VERSION ""

NS_ :

BS_:

BU_:

BO_ 915 VCU_EPB_1: 8 Vector__XXX
 SG_ VCU_WarnLampSts : 2|2@0+ (1,0) [3|0] "" Vector__XXX
 SG_ EPB_VehiclelongitudinalAcceleration : 16|12@0+ (0.01,-20.48) [20.46|-20.48] "m/s2" Vector__XXX

BO_ 792 ABS_2: 8 Vector__XXX
 SG_ ABS_EBDFaultSts : 8|1@0+ (1,0) [1|0] "" Vector__XXX
 SG_ ABS_ESCEnableSwSts : 9|1@0+ (1,0) [1|0] "" Vector__XXX
 SG_ ABS_ABSFaultSts : 10|1@0+ (1,0) [1|0] "" Vector__XXX
 SG_ ABS_AEBActiveSts : 11|1@0+ (1,0) [1|0] "" Vector__XXX
 SG_ ABS_AEBAvailableSts : 12|1@0+ (1,0) [1|0] "" Vector__XXX
 SG_ ABS_ABSActiveSts : 13|1@0+ (1,0) [1|0] "" Vector__XXX
 SG_ ABS_ESCFaultSts : 14|1@0+ (1,0) [1|0] "" Vector__XXX
 SG_ ABS_BrakePedalActiveSts : 15|1@0+ (1,0) [1|0] "" Vector__XXX
 SG_ ABS_EPBBrakeReq : 16|1@0+ (1,0) [1|0] "" Vector__XXX
 SG_ ABS_EBDWarnLamp : 17|1@0+ (1,0) [1|0] "" Vector__XXX
 SG_ ABS_ABSWarnLamp : 18|1@0+ (1,0) [1|0] "" Vector__XXX
 SG_ ABS_CarbonBrushFaulSts : 19|1@0+ (1,0) [1|0] "" Vector__XXX
 SG_ ABS_ACCControlActiveSts : 20|1@0+ (1,0) [1|0] "" Vector__XXX
 SG_ ABS_CurrentConfiguration : 21|1@0+ (1,0) [1|0] "" Vector__XXX
 SG_ ABS_ACCControlAvailableSts : 22|1@0+ (1,0) [1|0] "" Vector__XXX
 SG_ ABS_VehSpeedError : 23|1@0+ (1,0) [1|0] "" Vector__XXX
 SG_ ABS_VehSpeed : 32|16@0+ (0.01,0) [655.34|0] "kph" Vector__XXX

BO_ 713 ACM_IDM_4: 8 Vector__XXX
 SG_ IDM__LDW_SensSts : 22|2@0+ (1,0) [3|0] "" Vector__XXX

BO_ 1040 MCU_1: 8 Vector__XXX
 SG_ MCU_MotorSpd : 24|16@0+ (0.5,-12000) [12000|-12000] "rpm" Vector__XXX
 SG_ MCU_ActTorq : 40|16@0+ (0.05,-300) [300|-300] "Nm" Vector__XXX

BO_ 1312 TBOX_1: 8 Vector__XXX
 SG_ TBOX_RemoteAntiTheftReq : 16|2@0+ (1,0) [3|0] "" Vector__XXX

BO_ 710 ACM_IDM_4: 8 Vector__XXX
 SG_ IDM__AEB_EnableSts : 0|2@0+ (1,0) [3|0] "" Vector__XXX
 SG_ IDM__FCW_EnableSts : 2|2@0+ (1,0) [3|0] "" Vector__XXX
 SG_ IDM__LDW_EnableSts : 4|2@0+ (1,0) [3|0] "" Vector__XXX
 SG_ IDM__LCK_EnableSts : 6|2@0+ (1,0) [3|0] "" Vector__XXX
 SG_ IDM__TJA_EnableSts : 8|2@0+ (1,0) [3|0] "" Vector__XXX
 SG_ IDM__LimSpdEnableSts : 10|2@0+ (1,0) [3|0] "" Vector__XXX
 SG_ IDM__AutoHighLamp_EnableSts : 12|2@0+ (1,0) [3|0] "" Vector__XXX
 SG_ IDM__BSD_EnableSts : 14|2@0+ (1,0) [3|0] "" Vector__XXX
 SG_ IDM__DOW_EnableSts : 16|2@0+ (1,0) [3|0] "" Vector__XXX
 SG_ IDM__AHC_Dist_SetSts : 28|2@0+ (1,0) [3|0] "" Vector__XXX
 SG_ IDM__BSD_WarnSwSts : 30|2@0+ (1,0) [3|0] "" Vector__XXX
 SG_ IDM__FCW_WarnSwSts : 32|2@0+ (1,0) [3|0] "" Vector__XXX
 SG_ IDM__DOW_WarnSwSts : 34|2@0+ (1,0) [3|0] "" Vector__XXX
 SG_ IDM__RCTA_WarnSwSts : 36|2@0+ (1,0) [3|0] "" Vector__XXX

BO_ 1106 ICM_1: 8 Vector__XXX
 SG_ ICM_DriverSeatBeltSwSts : 41|1@0+ (1,0) [1|0] "" Vector__XXX
 SG_ ICM_TotalOdometer : 32|20@0+ (1,0) [999999|0] "km" Vector__XXX

BO_ 469 VCU_EPS_1: 8 Vector__XXX
 SG_ VCU_SystemFaultSts : 7|1@0+ (1,0) [1|0] "" Vector__XXX

BO_ 865 ACM_1: 8 Vector__XXX
 SG_ ACM_IntelliDriveModeReq_BCM : 0|1@0+ (1,0) [1|0] "" Vector__XXX
 SG_ ACM_ParkLightReq : 1|1@0+ (1,0) [1|0] "" Vector__XXX
 SG_ ACM_DRLReq : 2|1@0+ (1,0) [1|0] "" Vector__XXX
 SG_ ACM_LowBeamReq : 3|1@0+ (1,0) [1|0] "" Vector__XXX
 SG_ ACM_HighBeamReq : 4|1@0+ (1,0) [1|0] "" Vector__XXX
 SG_ ACM_FrontFogReq : 5|1@0+ (1,0) [1|0] "" Vector__XXX
 SG_ ACM_ReqrFogReq : 6|1@0+ (1,0) [1|0] "" Vector__XXX
 SG_ ACM_BrakeLightReq : 7|1@0+ (1,0) [1|0] "" Vector__XXX
 SG_ ACM_ReverseLightReq : 8|1@0+ (1,0) [1|0] "" Vector__XXX
 SG_ ACM_HornReq : 9|1@0+ (1,0) [1|0] "" Vector__XXX
 SG_ ACM_TurnLightReq_L : 10|1@0+ (1,0) [1|0] "" Vector__XXX
 SG_ ACM_TurnLightReq_R : 11|1@0+ (1,0) [1|0] "" Vector__XXX
 SG_ ACM_HazardLightReq : 12|1@0+ (1,0) [1|0] "" Vector__XXX
 SG_ ACM_WiperReq : 13|3@0+ (1,0) [7|0] "" Vector__XXX
 SG_ ACM_BuzzerRateReq : 16|2@0+ (1,0) [7|0] "" Vector__XXX

BO_ 793 ABS_3: 8 Vector__XXX
 SG_ ABS_WheelSpd_FL_Pulse : 0|8@0+ (1,0) [255|0] "" Vector__XXX
 SG_ ABS_WheelSpd_FL_Pulse_VD : 15|1@0+ (1,0) [1|0] "" Vector__XXX
 SG_ ABS_WheelSpd_FR_Pulse : 16|8@0+ (1,0) [255|0] "" Vector__XXX
 SG_ ABS_WheelSpd_FR_Pulse_VD : 31|1@0+ (1,0) [1|0] "" Vector__XXX
 SG_ ABS_WheelSpd_RL_Pulse : 32|8@0+ (1,0) [255|0] "" Vector__XXX
 SG_ ABS_WheelSpd_RL_Pulse_VD : 47|1@0+ (1,0) [1|0] "" Vector__XXX
 SG_ ABS_WheelSpd_RR_Pulse : 48|8@0+ (1,0) [255|0] "" Vector__XXX
 SG_ ABS_WheelSpd_RR_Pulse_VD : 63|1@0+ (1,0) [1|0] "" Vector__XXX

BO_ 545 ABS_4: 8 Vector__XXX
 SG_ ESC_YawRateValue : 12|12@0+ (0.05,-100) [104.7|-100] "deg/Sec." Vector__XXX
 SG_ ESC_LongitudinalAcceleration : 16|12@0+ (0.01,-20.48) [20.46|-20.48] "m/s2" Vector__XXX
 SG_ ESC_YawRateValue_VD : 32|1@0+ (1,0) [1|0] "" Vector__XXX
 SG_ ESC_LongitudinalAcceleration_VD : 33|1@0+ (1,0) [1|0] "" Vector__XXX
 SG_ ESC_LaterAccSensor_VD : 34|1@0+ (1,0) [1|0] "" Vector__XXX
 SG_ ESC_LaterAccSensor : 36|12@0+ (0.01,-20.48) [20.46|-20.48] "m/s2" Vector__XXX

BO_ 455 ACM_ADAS_1: 8 Vector__XXX
 SG_ ADAS_ACCFaultSts : 0|2@0+ (1,0) [3|0] "" Vector__XXX
 SG_ ADAS_ACCSystemSts : 2|3@0+ (1,0) [7|0] "" Vector__XXX
 SG_ ADAS_ACCStandbyReq : 5|1@0+ (1,0) [1|0] "" Vector__XXX
 SG_ ADAS_ACCTorqReq_VD : 6|1@0+ (1,0) [1|0] "" Vector__XXX
 SG_ ADAS_ACCTorqReq : 20|12@0+ (0.25,0) [1023.5|0] "Nm" Vector__XXX
 SG_ ADAS_ESCDecelerationReqValue : 24|12@0+ (0.01,-20.47) [20.47|-20.47] "m/s2" Vector__XXX
 SG_ ADAS_ESCDecelerationReqType : 40|2@0+ (1,0) [3|0] "" Vector__XXX
 SG_ ADAS_VCUDecelerationReq_VD : 43|1@0+ (1,0) [1|0] "" Vector__XXX
 SG_ ADAS_VCUDecelerationReq : 44|12@0+ (0.01,-20.47) [20.47|-20.47] "m/s2" Vector__XXX
 SG_ ADAS_MsgCounter_1 : 48|4@0+ (1,0) [15|0] "" Vector__XXX
 SG_ ADAS_FCWWarn : 52|2@0+ (1,0) [3|0] "" Vector__XXX
 SG_ ADAS_Cherksum_1 : 56|8@0+ (1,0) [255|0] "" Vector__XXX

BO_ 712 ACM_IDM_4: 8 Vector__XXX
 SG_ IDM__RCTA_EnableSts : 20|2@0+ (1,0) [3|0] "" Vector__XXX

BO_ 914 BCM_1: 8 Vector__XXX
 SG_ BCM_KeySts : 0|2@0+ (1,0) [3|0] "" Vector__XXX
 SG_ BCM_TurnLightSts_R : 2|1@0+ (1,0) [1|0] "" Vector__XXX
 SG_ BCM_TurnLightSts_L : 3|1@0+ (1,0) [1|0] "" Vector__XXX
 SG_ BCM_HazardLightSts : 4|1@0+ (1,0) [1|0] "" Vector__XXX
 SG_ BCM_ParkingLightSts : 5|1@0+ (1,0) [1|0] "" Vector__XXX
 SG_ BCM_HighBeamSts : 6|1@0+ (1,0) [1|0] "" Vector__XXX
 SG_ BCM_LowBeamSts : 7|1@0+ (1,0) [1|0] "" Vector__XXX
 SG_ BCM_DRLSts : 8|1@0+ (1,0) [1|0] "" Vector__XXX
 SG_ BCM_DoorAjarSts_Driver : 9|1@0+ (1,0) [1|0] "" Vector__XXX
 SG_ BCM_DoorAjarSts_Psngr : 10|1@0+ (1,0) [1|0] "" Vector__XXX
 SG_ BCM_DoorAjarSts_RR : 11|1@0+ (1,0) [1|0] "" Vector__XXX
 SG_ BCM_DoorAjarSts_RL : 12|1@0+ (1,0) [1|0] "" Vector__XXX
 SG_ BCM_TrunkAjarSts : 13|1@0+ (1,0) [1|0] "" Vector__XXX
 SG_ BCM_TrunkReleaseReq : 14|1@0+ (1,0) [1|0] "" Vector__XXX
 SG_ BCM_RearFogLightSts : 15|1@0+ (1,0) [1|0] "" Vector__XXX
 SG_ BCM_ACC_RelaySts : 18|1@0+ (1,0) [1|0] "" Vector__XXX
 SG_ BCM_ON_RelaySts : 19|1@0+ (1,0) [1|0] "" Vector__XXX
 SG_ BCM_AntiTheftMode : 20|3@0+ (1,0) [7|0] "" Vector__XXX
 SG_ BCM_EmergencyStrat : 23|1@0+ (1,0) [1|0] "" Vector__XXX
 SG_ BCM_EmergencyStop : 24|2@0+ (1,0) [3|0] "" Vector__XXX
 SG_ BCM_GearboxPositionSts : 26|1@0+ (1,0) [1|0] "" Vector__XXX
 SG_ BCM_VehStartEnableSts : 27|1@0+ (1,0) [1|0] "" Vector__XXX
 SG_ BCM_IGN_CtrlSource : 28|4@0+ (1,0) [15|0] "" Vector__XXX
 SG_ BCM_12V_BattVolt : 32|8@0+ (0.1,0) [25.4|0] "V" Vector__XXX
 SG_ BCM_DoorLockSts_Driver : 40|1@0+ (1,0) [1|0] "" Vector__XXX
 SG_ BCM_VehOperationInd : 41|3@0+ (1,0) [7|0] "" Vector__XXX
 SG_ BCM_DoorLockSts_Trunk : 44|1@0+ (1,0) [1|0] "" Vector__XXX
 SG_ BCM_OTA_Sts : 46|2@0+ (1,0) [3|0] "" Vector__XXX
 SG_ BCM_WinPostionSts_FL : 48|3@0+ (1,0) [7|0] "" Vector__XXX
 SG_ BCM_WinPostionSts_FR : 51|3@0+ (1,0) [7|0] "" Vector__XXX
 SG_ BCM_SoftAntiTheftSts : 54|1@0+ (1,0) [1|0] "" Vector__XXX
 SG_ BCM_Reserved_VehRentalSts : 55|1@0+ (1,0) [1|0] "" Vector__XXX
 SG_ BCM_SW_Flag : 56|2@0+ (1,0) [1|0] "" Vector__XXX
 SG_ BCM_WiperSts : 58|3@0+ (1,0) [7|0] "" Vector__XXX
 SG_ BCM_TurnLightDirection_L : 61|1@0+ (1,0) [1|0] "" Vector__XXX
 SG_ BCM_TurnLightDirection_R : 62|1@0+ (1,0) [1|0] "" Vector__XXX

BO_ 1129 BMS_1: 8 Vector__XXX
 SG_ BMS_SOC_Disp : 40|16@0+ (0.01,0) [100|0] "%" Vector__XXX

BO_ 1024 VCU_2: 8 Vector__XXX
 SG_ VCU_VehGradient : 48|8@0+ (0.1,-10) [10|-10] "m/s2" Vector__XXX

BO_ 768 ABS_1: 8 Vector__XXX
 SG_ ABS_WheelSpd_FL_VD : 6|2@0+ (1,0) [1|0] "" Vector__XXX
 SG_ ABS_WheelSpd_FL : 8|14@0+ (0.0625,0) [1023.875|0] "kps" Vector__XXX
 SG_ ABS_WheelSpd_FR_VD : 22|2@0+ (1,0) [1|0] "" Vector__XXX
 SG_ ABS_WheelSpd_FR : 24|14@0+ (0.0625,0) [1023.875|0] "kps" Vector__XXX
 SG_ ABS_WheelSpd_RL_VD : 38|2@0+ (1,0) [1|0] "" Vector__XXX
 SG_ ABS_WheelSpd_RL : 40|14@0+ (0.0625,0) [1023.875|0] "kps" Vector__XXX
 SG_ ABS_WheelSpd_RR_VD : 54|2@0+ (1,0) [1|0] "" Vector__XXX
 SG_ ABS_WheelSpd_RR : 56|14@0+ (0.0625,0) [1023.875|0] "kps" Vector__XXX

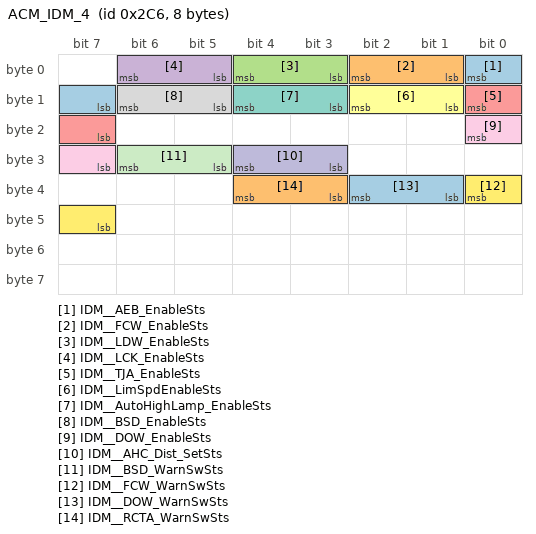
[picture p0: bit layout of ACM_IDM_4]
BO_ 711 ACM_IDM_4: 8 Vector__XXX
 SG_ IDM__RCW_EnableSts : 18|2@0+ (1,0) [3|0] "" Vector__XXX

BA_DEF_  "BusType" STRING ;
BA_DEF_DEF_  "BusType" "CAN";
